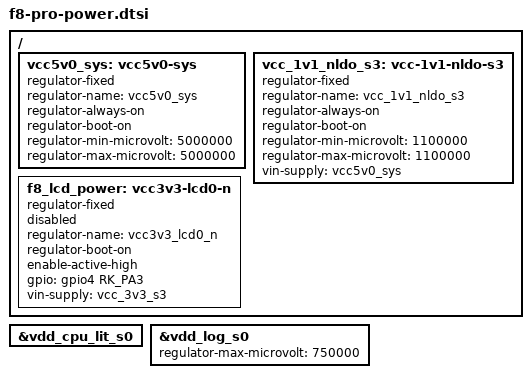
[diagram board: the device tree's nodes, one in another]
// SPDX-License-Identifier: GPL-2.0-only
// Development input, not a complete board or validated power-management policy.
#include "rk3588-rk806-single.dtsi"

/ {
	vcc5v0_sys: vcc5v0-sys {
		compatible = "regulator-fixed";
		regulator-name = "vcc5v0_sys";
		regulator-always-on;
		regulator-boot-on;
		regulator-min-microvolt = <5000000>;
		regulator-max-microvolt = <5000000>;
	};
	vcc_1v1_nldo_s3: vcc-1v1-nldo-s3 {
		compatible = "regulator-fixed";
		regulator-name = "vcc_1v1_nldo_s3";
		regulator-always-on;
		regulator-boot-on;
		regulator-min-microvolt = <1100000>;
		regulator-max-microvolt = <1100000>;
		vin-supply = <&vcc5v0_sys>;
	};
	f8_lcd_power: vcc3v3-lcd0-n {
		compatible = "regulator-fixed";
		regulator-name = "vcc3v3_lcd0_n";
		regulator-boot-on;
		enable-active-high;
		gpio = <&gpio4 RK_PA3 GPIO_ACTIVE_HIGH>;
		vin-supply = <&vcc_3v3_s3>;
		status = "disabled";
	};
};

&vdd_cpu_lit_s0 {
	/delete-property/ regulator-init-microvolt;
};

&vdd_log_s0 {
	regulator-max-microvolt = <750000>;
};
